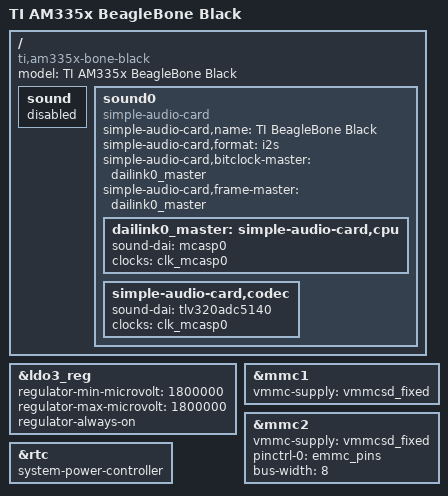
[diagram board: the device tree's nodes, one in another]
/*
 * Copyright (C) 2012 Texas Instruments Incorporated - http://www.ti.com/
 *
 * This program is free software; you can redistribute it and/or modify
 * it under the terms of the GNU General Public License version 2 as
 * published by the Free Software Foundation.
 */
/dts-v1/;

#include "am33xx.dtsi"
#include "am335x-bone-common.dtsi"

/ {
	model = "TI AM335x BeagleBone Black";
	compatible = "ti,am335x-bone-black", "ti,am335x-bone", "ti,am33xx";

	sound {
		status = "disabled"; /* Disable default HDMI sound card */
	};

	sound0: sound0 {
		compatible = "simple-audio-card";
		simple-audio-card,name = "TI BeagleBone Black";
		simple-audio-card,format = "i2s";
		simple-audio-card,bitclock-master = <&dailink0_master>;
		simple-audio-card,frame-master = <&dailink0_master>;

		dailink0_master: simple-audio-card,cpu {
			sound-dai = <&mcasp0>;
			clocks = <&clk_mcasp0>;
		};

		simple-audio-card,codec {
			sound-dai = <&tlv320adc5140>;
			clocks = <&clk_mcasp0>;
		};
	};
};

&ldo3_reg {
	regulator-min-microvolt = <1800000>;
	regulator-max-microvolt = <1800000>;
	regulator-always-on;
};

&mmc1 {
	vmmc-supply = <&vmmcsd_fixed>;
};

&mmc2 {
	vmmc-supply = <&vmmcsd_fixed>;
	pinctrl-names = "default";
	pinctrl-0 = <&emmc_pins>;
	bus-width = <8>;
	status = "okay";
};

&rtc {
	system-power-controller;
};
